AUTOSAR XML (schema 4-0-3)
package /AUTOSAR_ComM/SwComponentTypes
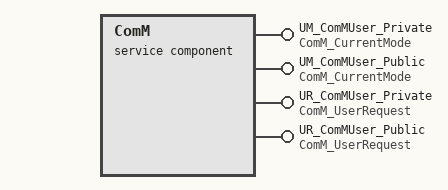
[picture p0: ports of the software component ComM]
  service sw component type ComM
    4 x provide port:
      UM_ComMUser_Private: mode-switch-sender-com-spec{mode-group=currentMode, queue-length=3}, provided-interface=ComM_CurrentMode
      UM_ComMUser_Public: mode-switch-sender-com-spec{mode-group=currentMode, queue-length=3}, provided-interface=ComM_CurrentMode
      UR_ComMUser_Private: provided-interface=ComM_UserRequest
        provided-com-specs:
          operation=RequestComMode, queue-length=1
          operation=GetCurrentComMode, queue-length=1
          operation=GetCurrentPNCComMode, queue-length=1
          operation=GetMaxComMode, queue-length=1
          operation=GetRequestedComMode, queue-length=1
      UR_ComMUser_Public: provided-interface=ComM_UserRequest
        provided-com-specs:
          operation=RequestComMode, queue-length=1
          operation=GetCurrentComMode, queue-length=1
          operation=GetCurrentPNCComMode, queue-length=1
          operation=GetMaxComMode, queue-length=1
          operation=GetRequestedComMode, queue-length=1
    behavior SwcInternalBehavior_0: data-type-mapping=DataTypeMappingSet_0, handle-termination-and-restart=NO-SUPPORT
      10 x operation invoked event:
        EV_GetCurrentComMode_ComMUser_Private: start-on-event=RE_GetCurrentComMode, operation=UR_ComMUser_Private.GetCurrentComMode
        EV_GetCurrentComMode_ComMUser_Public: start-on-event=RE_GetCurrentComMode, operation=UR_ComMUser_Public.GetCurrentComMode
        EV_GetCurrentPNCComMode_ComMUser_Private: start-on-event=RE_GetCurrentPNCComMode, operation=UR_ComMUser_Private.GetCurrentPNCComMode
        EV_GetCurrentPNCComMode_ComMUser_Public: start-on-event=RE_GetCurrentPNCComMode, operation=UR_ComMUser_Public.GetCurrentPNCComMode
        EV_GetMaxComMode_ComMUser_Private: start-on-event=RE_GetMaxComMode, operation=UR_ComMUser_Private.GetMaxComMode
        EV_GetMaxComMode_ComMUser_Public: start-on-event=RE_GetMaxComMode, operation=UR_ComMUser_Public.GetMaxComMode
        EV_GetRequestedComMode_ComMUser_Private: start-on-event=RE_GetRequestedComMode, operation=UR_ComMUser_Private.GetRequestedComMode
        EV_GetRequestedComMode_ComMUser_Public: start-on-event=RE_GetRequestedComMode, operation=UR_ComMUser_Public.GetRequestedComMode
        EV_RequestComMode_ComMUser_Private: start-on-event=RE_RequestComMode, operation=UR_ComMUser_Private.RequestComMode
        EV_RequestComMode_ComMUser_Public: start-on-event=RE_RequestComMode, operation=UR_ComMUser_Public.RequestComMode
      port-api-options:
        enable-take-address=true, indirect-api=false, port=UM_ComMUser_Public
        {enable-take-address=false, indirect-api=false, port-defined-argument-value{value=0, value-type=ComM_UserHandleType}, port=UR_ComMUser_Public}
        enable-take-address=true, indirect-api=false, port=UM_ComMUser_Private
        {enable-take-address=false, indirect-api=false, port-defined-argument-value{value=1, value-type=ComM_UserHandleType}, port=UR_ComMUser_Private}
      7 x runnable:
        RE_GetCurrentComMode: arguments=[symbol=pdav0, symbol=ComMode], can-be-invoked-concurrently=true, symbol=ComM_Rte_GetCurrentComMode
        RE_GetCurrentPNCComMode: arguments=[symbol=pdav0, symbol=ComMode], can-be-invoked-concurrently=true, symbol=ComM_Rte_GetCurrentPNCComMode
        RE_GetMaxComMode: arguments=[symbol=pdav0, symbol=ComMode], can-be-invoked-concurrently=true, symbol=ComM_Rte_GetMaxComMode
        RE_GetRequestedComMode: arguments=[symbol=pdav0, symbol=ComMode], can-be-invoked-concurrently=true, symbol=ComM_Rte_GetRequestedComMode
        RE_Main_0: symbol=ComM_MainFunction_0
          mode switch point MSP_ComMUser_Public: mode-group=UM_ComMUser_Public.currentMode
        RE_Main_1: symbol=ComM_MainFunction_1
          mode switch point MSP_ComMUser_Private: mode-group=UM_ComMUser_Private.currentMode
        RE_RequestComMode: arguments=[symbol=pdav0, symbol=ComMode], can-be-invoked-concurrently=true, symbol=ComM_Rte_RequestComMode
package /EB_ComM/SwcImplementations
  swc implementation SwcImplementation_0: programming-language=C, sw-version=5.19.8, vendor-id=1, behavior=SwcInternalBehavior_0
    code-descriptors:
      code ComMCode: artifact-descriptors=autosar-engineering-object={short-label=EngObject, category=SWSRC}
    resource consumption Resources
      memory section CODE: sw-addrmethod=CODE
